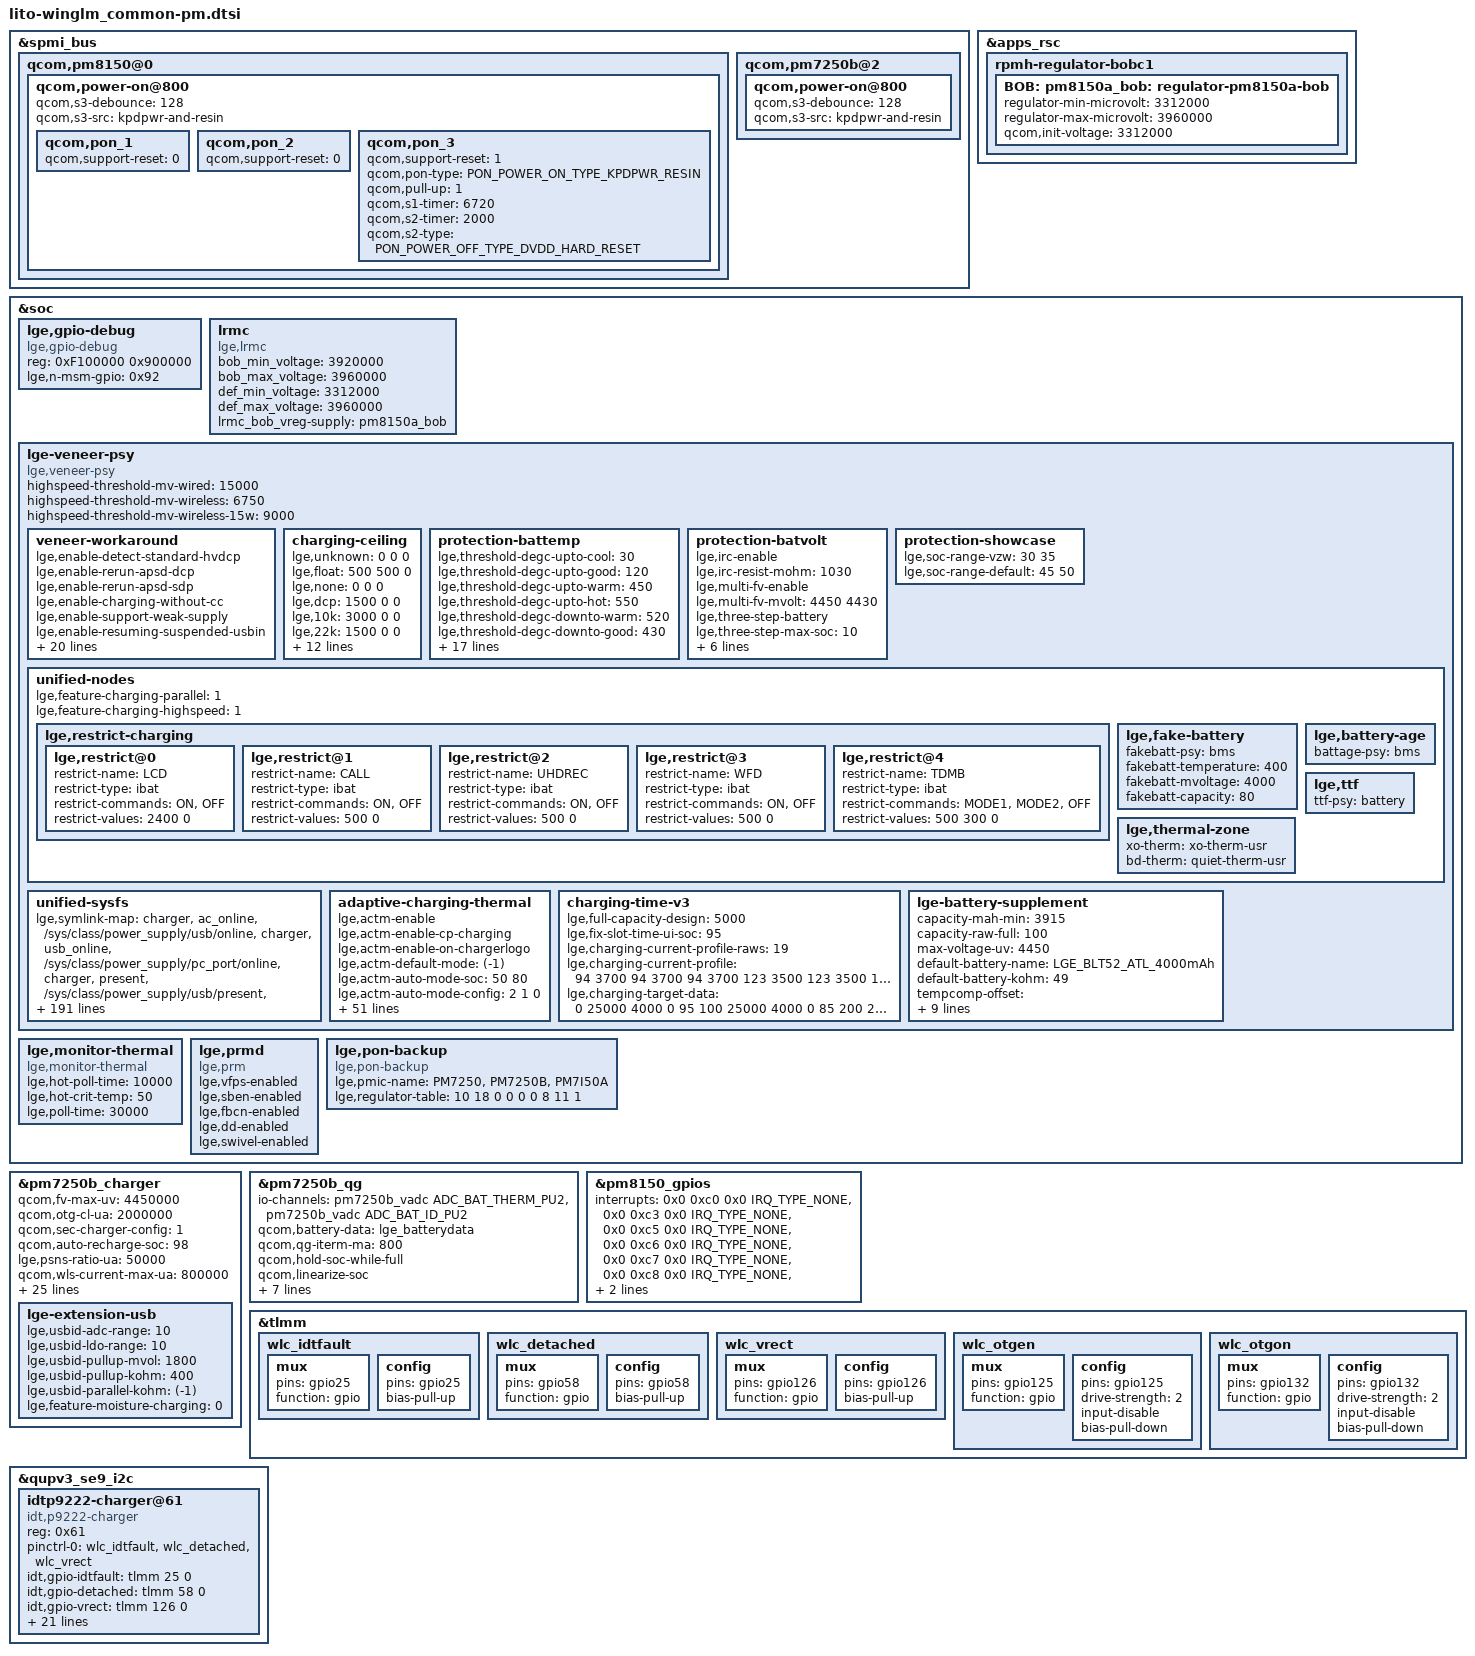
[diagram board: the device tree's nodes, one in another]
// SPDX-License-Identifier: GPL-2.0-only
/*
 * Copyright (c) 2018-2019, The Linux Foundation. All rights reserved.
 */

/* boot_images/QcomPkg/SocPkg/SaipanPkg/Settings/PMIC/pm_spmi_config.c */

&spmi_bus {
	qcom,pm8150@0 {
		qcom,power-on@800 {
			qcom,s3-debounce = <128>;
			qcom,s3-src = "kpdpwr-and-resin";

			qcom,pon_1 {
				/* KPD_PWR_N */
				status = "ok";
				qcom,support-reset = <0>;
			};

			qcom,pon_2 {
				/* RESIN_N */
				status = "ok";
				qcom,support-reset = <0>;
			};

			qcom,pon_3 {
				/* KPD_PWR_N AND RESIN_N */
				status = "ok";
				qcom,support-reset = <1>;
				qcom,pon-type = <PON_POWER_ON_TYPE_KPDPWR_RESIN>;
				qcom,pull-up = <1>;
				qcom,s1-timer = <6720>;
				qcom,s2-timer = <2000>;
				qcom,s2-type = <PON_POWER_OFF_TYPE_DVDD_HARD_RESET>;
			};
		};
	};

	qcom,pm7250b@2 {
		qcom,power-on@800 {
			qcom,s3-debounce = <128>;
			qcom,s3-src = "kpdpwr-and-resin";
		};
	};
};

&apps_rsc {
	rpmh-regulator-bobc1 {
		BOB: pm8150a_bob: regulator-pm8150a-bob {
			regulator-min-microvolt = <3312000>;
			regulator-max-microvolt = <3960000>;
			qcom,init-voltage = <3312000>;
		};
	};
};

&soc {
	lge,gpio-debug {
		compatible = "lge,gpio-debug";
		reg = <0xF100000 0x900000>;
		reg-names = "tlmm-base";
		lge,n-msm-gpio = <0x92>; /* SM7250 0 to 145 */
	};

	lrmc {
		compatible = "lge,lrmc";
		bob_min_voltage    = <3920000>;
		bob_max_voltage    = <3960000>;
		def_min_voltage    = <3312000>;
		def_max_voltage    = <3960000>;
		lrmc_bob_vreg-supply = <&pm8150a_bob>;
	};
	lge-veneer-psy {
		compatible = "lge,veneer-psy";
		status = "ok";
		highspeed-threshold-mv-wired = <15000>;
		highspeed-threshold-mv-wireless = <6750>;
		highspeed-threshold-mv-wireless-15w = <9000>;

		veneer-workaround {
			lge,enable-detect-standard-hvdcp;
			lge,enable-rerun-apsd-dcp;
			lge,enable-rerun-apsd-sdp;
			lge,enable-charging-without-cc;
			lge,enable-support-weak-supply;
			lge,enable-resuming-suspended-usbin;
			lge,enable-charging-with-rd;
			lge,enable-clear-power-role;
			//lge,enable-clear-dc-reverse-volt;
			lge,enable-clear-dc-reverse-volt-v2;
			lge,enable-avoid-fod-status;
			lge,enable-dcin-rerun-aicl;
			lge,enable-recovery-vashdn-wireless;
			lge,enable-retry-vconn-with-oc;
			lge,enable-retry-ok-to-pd;
			lge,enable-protect-overcharging;
			lge,enable-faked-usb-type;
			lge,enable-recover-cc;
			lge,enable-retry-apsd-with-factory;
			lge,enable-faster-try-apsd;
			lge,enable-faster-try;
			lge,enable-charging-for-mcdodo;
			lge,enable-disable-otg-hiccup;
			lge,enable-disable-cp-with-fake-mode;
			lge,enable-comp-cp-qc30;
			lge,enable-concurrency-otg-wlc;
			lge,enable-bad-operation-pps-ta;
		};

		charging-ceiling {
		/*	               iusb ibat  idc  : 0 means UNCEILING */
			lge,unknown = <   0    0    0>;
			lge,float   = < 500  500    0>;
			lge,none    = <   0    0    0>;

			lge,dcp     = <1500    0    0>;
			lge,10k     = <3000    0    0>;
			lge,22k     = <1500    0    0>;
			lge,qc2     = <1800    0    0>;
			lge,qc3     = <1800    0    0>;

			lge,usb2    = < 500    0    0>;
			lge,usb3    = < 900    0    0>;
			lge,cdp     = <1500 1500    0>;
			lge,pd      = <   0    0    0>;

			lge,56k     = <1500  500    0>;
			lge,130k    = <1500  500    0>;
			lge,910k    = <1500  500    0>;

			lge,w5w     = <   0    0  900>;
			lge,w9w     = <   0    0  900>;
			lge,w15w    = <   0    0 1200>;
		};

		protection-battemp {
			lge,threshold-degc-upto-cool = <30>;
			lge,threshold-degc-upto-good = <120>;
			lge,threshold-degc-upto-warm = <450>;
			lge,threshold-degc-upto-hot = <550>;
			lge,threshold-degc-downto-warm = <520>;
			lge,threshold-degc-downto-good = <430>;
			lge,threshold-degc-downto-cool = <100>;
			lge,threshold-degc-downto-cold = <0>;

			lge,period-ms-emergency	= <10000>;
			lge,period-ms-warning	= <30000>;
			lge,period-ms-normal	= <60000>;

		// parameters for warning status cool and warm
			lge,cool-mv-alert	= <4000>;
			lge,cool-ma-alert	= <500>;	// fixed 500 mA
			lge,cool-ma-pct		= <30>;		// means 0.3C rate

			lge,warm-mv-float	= <4000>;
			lge,warm-ma-pct		= <50>;		// means 0.5C rate

		// parameters for battery protection at chilly status
            lge,chilly-status-support;
            lge,chilly-degc-lowerbound = <0>;
            lge,chilly-degc-upperbound = <150>;
            lge,chilly-mv-alert    = <4000>;
            lge,chilly-mv-bound     = <200>;
            lge,chilly-ma-alert    = <630>;
            lge,chilly-ma-pct      = <50>;  // means 0.5C rate under batvol 4V
		};

		protection-batvolt {
			lge,irc-enable;
			lge,irc-resist-mohm = <1030>;
			lge,multi-fv-enable;
			lge,multi-fv-mvolt = <4450 4430>;  /* <CC_FV, CV_FV> */

			lge,three-step-battery;
			lge,three-step-max-soc = <10>;      // when soc exceed this value, disable maximum c-rate
			lge,threshold-vbat-limit = <4000 4200>;
			lge,threshold-vbat-clear = <3950 4150>;
			lge,threshold-ibat-pct = <100 60>;	// 1C = 3915mA, 0.6C = 2349mA
			// the below for two-step battery
			// lge,threshold-vbat-limit = <4250>;
			// lge,threshold-vbat-clear = <4200>;
			// lge,threshold-ibat-pct = <60>;	// means 0.6C rate

			lge,threshold-cv-ibat-pct = <34>;	// means 0.34C = 1331mA

			lge,step-ibat-ma = <100>;
			lge,step-poll-ms = <5000>;
		};

		protection-showcase {
			lge,soc-range-vzw     = <30 35>;
			lge,soc-range-default = <45 50>;
		};

		unified-nodes {
			lge,feature-charging-parallel = <1>;
			lge,feature-charging-highspeed = <1>;

			lge,restrict-charging {
				// restrict-values 0 means UNCEILING

				lge,restrict@0 {
					restrict-name = "LCD";
					restrict-type = "ibat";
					restrict-commands = "ON", "OFF";
					restrict-values = <2400      0>;
				};
				lge,restrict@1 {
					restrict-name = "CALL";
					restrict-type = "ibat";
					restrict-commands = "ON", "OFF";
					restrict-values = < 500      0>;
				};
				lge,restrict@2 {
					restrict-name = "UHDREC";
					restrict-type = "ibat";
					restrict-commands = "ON", "OFF";
					restrict-values = < 500      0>;
				};
				lge,restrict@3 {
					restrict-name = "WFD";
					restrict-type = "ibat";
					restrict-commands = "ON", "OFF";
					restrict-values = < 500      0>;
				};
				lge,restrict@4 {
					restrict-name = "TDMB";
					restrict-type = "ibat";
					restrict-commands = "MODE1", "MODE2", "OFF";
					restrict-values = <    500      300      0>;
				};
			};

			lge,fake-battery {
				fakebatt-psy = "bms";		// What 'psy' does implement(or support) the fake battery?
				fakebatt-temperature = <400>;
				fakebatt-mvoltage = <4000>;
				fakebatt-capacity = <80>;
			};

			lge,battery-age {
				battage-psy = "bms";		// What 'psy' does implement(or support) the battery age?
			};

			lge,thermal-zone {
				xo-therm = "xo-therm-usr";
				bd-therm = "quiet-therm-usr";
			};

			lge,ttf {
				ttf-psy = "battery";	// What 'psy' does implement(or support) the time to full now?
			};
		};

		unified-sysfs {
			lge,symlink-map =
			/* group , user_node, kernel node */
			/* Charger */
			"charger",                     "ac_online", "/sys/class/power_supply/usb/online",
			"charger",                    "usb_online", "/sys/class/power_supply/pc_port/online",
			"charger",                       "present", "/sys/class/power_supply/usb/present",
			"charger",                    "wlc_online", "/sys/class/power_supply/wireless/online",
			"charger",                          "type", "/sys/class/power_supply/usb/real_type",
			"charger",                   "usb_pd_type", "/sys/class/power_supply/usb/real_type",
			"charger",                      "time_out", "/sys/class/power_supply/battery/safety_timer_enabled",
			"charger",              "charging_enabled", "/sys/devices/platform/lge-unified-nodes/charging_enable",
			"charger",                  "ibat_current", "/sys/class/power_supply/battery/current_now",
			"charger",                  "ichg_current", "/sys/class/power_supply/usb/current_max",
			"charger",                  "iusb_control", "NULL",
			"charger",            "thermal_mitigation", "NULL",
			"charger",        "wlc_thermal_mitigation", "/sys/class/power_supply/wireless/current_max",
			"charger",       "usb_parallel_chg_status", "NULL",
			"charger", "usb_parallel_charging_enabled", "/sys/class/power_supply/charge_pump_master/charging_enabled",
			"charger", "factory_parallel_charger_test", "/sys/devices/platform/lge-unified-nodes/support_fastpl",
			"charger",            "moisture_detection", "/sys/class/power_supply/usb/moisture_detected",
			"charger",           "restricted_charging", "/sys/devices/platform/lge-unified-nodes/charging_restriction",
			"charger",              "ibat_max_current", "/sys/class/power_supply/battery/constant_charge_current_max",
			"charger",                       "chgstep", "/sys/devices/platform/lge-unified-nodes/charging_step",
			"charger",               "connection_type", "NULL",
			"charger",                       "fastchg", "/sys/devices/platform/lge-unified-nodes/charger_highspeed",
			"charger",         "input_current_settled", "/sys/class/power_supply/usb/input_current_settled",
			"charger",            "store_demo_enabled", "NULL",
			"charger",     "wireless_charging_enabled", "/sys/class/power_supply/wireless/charging_enabled",
			"charger",                 "input_suspend", "/sys/class/power_supply/battery/input_suspend",
			"charger",                  "incompatible", "/sys/devices/platform/lge-unified-nodes/charger_incompatible",
			"charger",                    "hvdcp_fake", "/sys/devices/platform/lge-unified-nodes/fake_hvdcp",
			"charger",               "usb_current_max", "/sys/devices/platform/lge-unified-nodes/fake_sdpmax",
			"charger",               "fastchg_support", "/sys/devices/platform/lge-unified-nodes/support_fastchg",
			"charger",                    "usbid_type", "/sys/class/power_supply/usb/resistance_id",
			"charger",          "typec_cc_orientation", "/sys/class/power_supply/usb/typec_cc_orientation",
			//"charger",                 "ccd_batchg_en", "/sys/devices/platform/lge-unified-nodes/ccd_batchg_en",
			//"charger",             "ccd_input_suspend", "/sys/devices/platform/lge-unified-nodes/ccd_input_suspend",
			//"charger",                       "ccd_icl", "/sys/devices/platform/lge-unified-nodes/ccd_icl",
			//"charger",                       "ccd_fcc", "/sys/devices/platform/lge-unified-nodes/ccd_fcc",
			//"charger",                    "ccd_vfloat", "/sys/devices/platform/lge-unified-nodes/ccd_vfloat",
			//"charger",                     "aicl_done", "/sys/devices/platform/lge-unified-nodes/aicl_done",
			/* ADC/MPP */
			"adc",              "thermal", "/sys/class/thermal/",
			"adc",             "xo_therm", "/sys/bus/iio/devices/iio:device0/in_temp_xo_therm_input",
			"adc",           "batt_therm", "/sys/class/power_supply/battery/temp",
			"adc",              "batt_id", "/sys/devices/platform/lge-unified-nodes/battery_valid",
			"adc",            "pa_therm1", "/sys/bus/iio/devices/iio:device0/in_temp_pa_therm1_input",
			"adc",            "pa_therm2", "/sys/bus/iio/devices/iio:device2/in_temp_pa_therm2_input",
			"adc",            "pa_therm3", "/sys/bus/iio/devices/iio:device1/in_temp_bmr_s_therm_input",
			"adc",           "quiet_therm","/sys/bus/iio/devices/iio:device1/in_temp_charger_skin_therm_input",
			"adc",               "usb_in", "/sys/class/power_supply/usb/voltage_now",
			"adc",                "vcoin", "/sys/bus/iio/devices/iio:device0/in_voltage_vcoin_input",
			"adc",              "vph_pwr", "/sys/bus/iio/devices/iio:device0/in_voltage_vph_pwr_input",
			"adc",               "usb_id", "/sys/devices/platform/lge-unified-nodes/charger_usbid",
			"adc",             "usb_edge", "NULL",
			"adc",                 "pmic", "/sys/class/thermal/thermal_zone53/temp",
			"adc",                  "vts", "/sys/bus/platform/drivers/monitor-thermal/soc:lge,monitor-thermal/vts_temp",
			/* Battery */
			"battery",         "capacity", "/sys/class/power_supply/battery/capacity",
			"battery",           "health", "/sys/class/power_supply/battery/health",
			"battery",          "present", "/sys/class/power_supply/battery/present",
			"battery",      "pseudo_batt", "/sys/devices/platform/lge-unified-nodes/fake_battery",
			"battery",           "status", "/sys/class/power_supply/battery/status",
			"battery",       "status_raw", "NULL",
			"battery",             "temp", "/sys/class/power_supply/battery/temp",
			"battery",    "valid_batt_id", "/sys/devices/platform/lge-unified-nodes/battery_valid",
			"battery",      "voltage_now", "/sys/class/power_supply/battery/voltage_now",
			"battery",          "vzw_chg", "/sys/devices/platform/lge-unified-nodes/charger_verbose",
			"battery",     "raw_capacity", "/sys/class/power_supply/bms/capacity_raw",
			"battery",        "condition", "/sys/devices/platform/lge-unified-nodes/battery_condition",
			"battery",      "battery_age", "/sys/devices/platform/lge-unified-nodes/battery_age",
			"battery","battery_age_level", "/sys/devices/platform/lge-unified-nodes/battery_age",
			"battery",            "cycle", "/sys/devices/platform/lge-unified-nodes/battery_cycle",
			"battery",     "battery_type", "/sys/class/power_supply/bms/battery_type",
			"battery",      "charge_full", "/sys/class/power_supply/bms/charge_full",
			"battery",   "charge_now_raw", "/sys/class/power_supply/bms/charge_now_raw",
			"battery", "time_to_full_now", "/sys/class/power_supply/battery/time_to_full_now",
			//"battery",     "ttf_capacity", "/sys/devices/platform/lge-unified-nodes/ttf_capacity",
			//"battery", "time_to_full_now", "/sys/devices/platform/lge-unified-nodes/time_to_full_now",
			//"battery",   "bsm_timetofull", "/sys/devices/platform/lge-unified-nodes/bsm_timetofull",
			/* LCD Backlight */
			"lcd",           "brightness", "/sys/class/backlight/panel0-backlight/brightness",
			"lcd",       "max_brightness", "/sys/class/backlight/panel0-backlight/max_brightness",
			"lcd_ex",        "brightness", "NULL",
			"lcd_ex",    "max_brightness", "NULL",
			/* KEY LED */
			"key_led",   "red_brightness", "/sys/class/leds/red/brightness",
			"key_led", "green_brightness", "/sys/class/leds/green/brightness",
			"key_led",  "blue_brightness", "/sys/class/leds/blue/brightness",
			/* CPU */
			"cpu",       "cpu_idle_modes", "NULL",
			/* GPU */
			"gpu",                 "busy", "/sys/class/kgsl/kgsl-3d0/gpubusy",
			"gpu",               "gpuclk", "/sys/class/kgsl/kgsl-3d0/gpuclk",
			/* PLATFORM */
			"platform",       "speed_bin", "NULL",
			"platform",         "pvs_bin", "NULL",
			"platform",   "poweron_alarm", "/sys/module/qpnp_rtc/parameters/poweron_alarm",
			"platform",         "pcb_rev", "/sys/bus/iio/devices/iio:device2/in_voltage_pmic_hardware_id_input",
			"platform",       "smpl_boot", "/sys/module/lge_smpl_count/parameters/smpl_boot",
			/* testmode */
			"testmode",            "temp", "/sys/class/power_supply/battery/temp",
			"testmode",     "voltage_now", "/sys/class/power_supply/battery/voltage_now",
			"testmode",          "usb_id", "/sys/devices/platform/lge-unified-nodes/charger_usbid",
			"testmode",         "batt_id", "/sys/devices/platform/lge-unified-nodes/battery_valid",
			"testmode",         "fuelval", "/sys/class/power_supply/battery/capacity",
			"testmode",        "xo_therm", "/sys/devices/platform/lge-unified-nodes/factory_xo_therm",
			"testmode",          "charge", "/sys/class/power_supply/battery/battery_charging_enabled",
			"testmode",          "chcomp", "/sys/devices/platform/lge-unified-nodes/charging_completed",
			"testmode",           "usbin", "/sys/class/power_supply/usb/voltage_now",
			"testmode",       "pa_therm1", "/sys/bus/iio/devices/iio:device0/in_temp_pa_therm1_input",
			"testmode",       "pa_therm2", "/sys/bus/iio/devices/iio:device2/in_temp_pa_therm2_input",
			"testmode",       "pa_therm3", "/sys/bus/iio/devices/iio:device1/in_temp_bmr_s_therm_input",
			"testmode",       "bd_therm2", "/sys/devices/platform/lge-unified-nodes/factory_bd_therm",
			"testmode",           "vcoin", "/sys/bus/iio/devices/iio:device0/in_voltage_vcoin_input",
			"testmode",         "vph_pwr", "/sys/bus/iio/devices/iio:device0/in_voltage_vph_pwr_input",
			"testmode",     "current_now", "/sys/class/power_supply/battery/current_now",
			"testmode",     "current_max", "/sys/class/power_supply/usb/current_max",
			"testmode",         "pcb_rev", "/sys/bus/iio/devices/iio:device2/in_voltage_pmic_hardware_id_input",
			"testmode",      "chgmodeoff", "/sys/class/power_supply/battery/input_suspend",
			"testmode",         "fuelrst", "/sys/class/power_supply/battery/present",
			"testmode",        "rtc_time", "/dev/rtc0",
			"testmode",           "pmrst", "NULL",
			"testmode",        "battexit", "/sys/class/power_supply/battery/present",
			"testmode",  "hardreset_mode", "NULL",
			/* ps feature*/
			"psfeature",     "vfps_ratio", "/sys/class/power/vfps/vfps_ratio",
			"psfeature",           "vfps", "/sys/class/power/vfps/vfps",
			"psfeature",      "vfps_fcnt", "/sys/class/power/vfps/vfps_fcnt",
			"psfeature",  "triton_policy", "/sys/class/power/triton/cur_policy",
			"psfeature",   "cancun_is_cm", "NULL",
			"regulator",       "vreg_bob", "/sys/devices/platform/soc/soc:lrmc/bob_mode";
		};

		adaptive-charging-thermal {
			lge,actm-enable;
			lge,actm-enable-cp-charging;                    // whether cp charging is supported.
			lge,actm-enable-on-chargerlogo;                 // the actm operates charging first mode in chargerlogo
			lge,actm-default-mode = <(-1)>;                 // 0-thermal first, 1-balanced, 2-charging first, 3-auto
			/*  actm auto mode description
			 *                     48%            77%
			 *    2-charging first  |  1-balacned  |  0-thermal first */
			lge,actm-auto-mode-soc = <50 80>;               // those values are raw soc.
			lge,actm-auto-mode-config = <2 1 0>;            // <2 1 0> means actm mode
			lge,actm-lcdon-temp-offset = <20>;              // unit: 0.1 degree

			lge,wired-therm-sensor-type = <21>;             // bit(0)-BATT, bit(1)-VTS, Two Digit -> <$(LCDON)$(LCDOFF)>
			lge,wired-wton-backward-margin = <10>;          // temp margin when it transit from WARM to NORM.
			lge,wired-temp-offset = <(-30) 0 0>;            // thermal first, balanced, charging first
			lge,wired-max-hold-criteria = <500 700 1000>;   // allow rising 1 degree per 20/14/10/min
			lge,wired-stage-size = <3>;
			lge,wired-target-temp = <300 340 380>;
			lge,wired-current-limit-ma = <3100 1500 500>;   // 0-normal, 1-warm, 2-hot
			lge,wired-curr-cp-limit-ma = <5100 3200>;       // extension of lge,wired-current-limit-ma
			                                                // 0-normal & pps, 1-normal & qc3.0
			lge,wired-max-fcc-ma = <5100 3200 3100>;        // 0-pps ta, 1- qc3.0 ta, 2-qc2.0 ta
			lge,wired-current-step-size = <3>;
			lge,wired-current-step-temp = <5 15 30>;
			lge,wired-current-step-ma = <100 200 400>;
			lge,wired-timer-ms = <60000>;

			/* wired sidecar */
			lge,wired-sidecar-enable = <0 0 1>;             // <Thermal first, balanced, charging first>
			lge,wired-sidecar-therm-enter-temp = <380 400>;     // <LCD_OFF, LCD_ON>
			lge,wired-sidecar-therm-exit-temp = <370 390>;      // <LCD_OFF, LCD_ON>
			lge,wired-sidecar-therm-min-current = <1000 500>;   // <LCD_OFF, LCD_ON>
			lge,wired-sidecar-bal-enter-temp = <380 400>;       // <LCD_OFF, LCD_ON>
			lge,wired-sidecar-bal-exit-temp = <370 390>;        // <LCD_OFF, LCD_ON>
			lge,wired-sidecar-bal-min-current = <1000 500>;     // <LCD_OFF, LCD_ON>
			lge,wired-sidecar-chg-enter-temp = <380 400>;       // <LCD_OFF, LCD_ON>
			lge,wired-sidecar-chg-exit-temp = <370 390>;        // <LCD_OFF, LCD_ON>
			lge,wired-sidecar-chg-min-current = <1000 500>;     // <LCD_OFF, LCD_ON>

			lge,wireless-therm-sensor-type = <33>;          // bit(0)-BATT, bit(1)-VTS, Two Digit -> <$(LCDON)$(LCDOFF)>
			lge,wireless-wton-backward-margin = <0>;        // temp margin when it transit from WARM to NORM.
			lge,wireless-temp-offset = <(-30) 0 0>;         // thermal first, balanced, charging first
			lge,wireless-max-hold-criteria = <250 333 500>; // allow rising 1 degree per 40/30/20min
			lge,wireless-stage-size = <3>;
			lge,wireless-target-temp = <320 380 420>;
			lge,wireless-epp-power-limit-mw = <6300 4050 3000>;
			lge,wireless-bpp-power-limit-mw = <4200 3900 3000>;
			lge,wireless-15w-max-power-mw = <0 0 7200>; // <Thermal first, balanced, charging first>
			lge,wireless-power-step-size = <3>;
			lge,wireless-power-step-temp = <5 15 30>;
			lge,wireless-epp-power-step-mw = <450 900 1350>;
			lge,wireless-bpp-power-step-mw = <300 600 900>;
			lge,wireless-timer-ms = <60000>;

			/* wireless sidecar */
			lge,wireless-sidecar-enable = <0 0 1>;          // <Thermal first, balanced, charging first>
			lge,wireless-sidecar-therm-enter-temp = <420 420>;  // <LCD_OFF, LCD_ON>
			lge,wireless-sidecar-therm-exit-temp = <400 400>;   // <LCD_OFF, LCD_ON>
			lge,wireless-sidecar-therm-min-power = <3000 3000>; // <LCD_OFF, LCD_ON>
			lge,wireless-sidecar-bal-enter-temp = <420 420>;    // <LCD_OFF, LCD_ON>
			lge,wireless-sidecar-bal-exit-temp = <400 400>;     // <LCD_OFF, LCD_ON>
			lge,wireless-sidecar-bal-min-power = <3000 3000>;   // <LCD_OFF, LCD_ON>
			lge,wireless-sidecar-chg-enter-temp = <420 420>;    // <LCD_OFF, LCD_ON>
			lge,wireless-sidecar-chg-exit-temp = <400 400>;     // <LCD_OFF, LCD_ON>
			lge,wireless-sidecar-chg-min-power = <3000 3000>;   // <LCD_OFF, LCD_ON>
		};

		charging-time-v3 {
			lge,full-capacity-design = <5000>;
			lge,fix-slot-time-ui-soc = <95>;

			lge,charging-current-profile-raws = <19>;  /* max: 20 */
			lge,charging-current-profile = <
			/* format: raw_soc, raw_current(mA) */
			/* | Thermal |  | Balanced | | Charging | */
				 94  3700     94  3700     94  3700
				123  3500    123  3500    123  3500
				139  3400    139  3400    139  3400
				153  3300    153  3300    153  3300
				164  3000    164  3000    164  3000
				178  2600    178  2600    178  2600
				181  2300    181  2300    181  2300
				221  2200    221  2200    221  2200
				233  1800    233  1800    233  1800
				239  1500    239  1500    239  1500
				245  1300    245  1300    245  1300
				247  1220    247  1220    247  1220
				248  1170    248  1170    248  1170
				249  1100    249  1100    249  1100
				250  1040    250  1040    250  1040
				251   960    251   960    251   960
				252   900    252   900    252   900
				253   850    253   850    253   850
				254   800    254   800    254   800   /* <- END -> */
			>;

			lge,charging-target-data = <
	/* format : type, power(mW), current(mA), down(uA), target(min) */
	/* cp pps  thermal  */    0    25000    4000       0     95
	/*         balanced */  100    25000    4000       0     85
	/*         charging */  200    25000    4850       0     80
	/* CP QC3  thermal  */    1    16200    3000       0    105
	/*         balanced */  101    16200    3000       0     95
	/*         charging */  201    16200    3200       0     90
	/* QC2     thermal  */    2    15000    2600       0    105
	/*         balanced */  102    15000    2600       0     95
	/*         charging */  202    15000    3100       0     90
	/* DCP     thermal  */    2     7500    1650     881    150
	/*         balanced */  102     7500    1650     881    150
	/*         charging */  202     7500    1650     881    150
	/* SDP     thermal  */    2     2500     500       0    485
	/*         balanced */  102     2500     500       0    485
	/*         charging */  202     2500     500       0    485
	/* WLC EPP thermal  */    3     7200    1750    2224    190
	/*         balanced */  103     7200    1750    2224    190
	/*         charging */  203     7200    1750    1032    175
	/* WLC BPP thermal  */    3     4500    1100     920    225
	/*         balanced */  103     4500    1100     920    225
	/*         charging */  203     4500    1100     640    205
	/* BCC     thermal  */    4    12500    2000       0    125
	/*         balanced */  104    12500    2000       0    125
	/*         charging */  204    12500    2000       0    125
			>;
		};

		lge-battery-supplement {
			capacity-mah-min = <3915>;
			capacity-raw-full = <100>;
			max-voltage-uv = <4450>;

			default-battery-name = "LGE_BLT52_ATL_4000mAh";
			default-battery-kohm = <49>;

			/* format : (temp index) (temp delta) */
			tempcomp-offset = <
				(-300) (-45)
				(-222) (-28)
				(-178) (-22)
				(-130) (-20)
				( -79) (-21)
				( -31) (-19)
				( -10) (-17)
				   15  (-15)
				   63  (-13)
				  110  (-10)
				  159  ( -9)
				  208  ( -9)
				  257  ( -7)
				  306  ( -7)
				  356  ( -6)
				  405  ( -5)
				  456  ( -6)
				  507  ( -7)
				  557  ( -8)
				  609  (-10)
				  662  (-13)
				  700  (-13)
				  730  (-13)
				  750  (-13)
				  800  (-13)
			>;

			tempcomp-offset-wlc-enable;
			tempcomp-offset-wlc-rise-filter-trigger = <430>;
			tempcomp-offset-wlc-lcdoff = <
				(-300) (-45)
				(-222) (-28)
				(-178) (-22)
				(-130) (-20)
				( -79) (-21)
				( -31) (-19)
				( -10) (-17)
				   15  (-15)
				   63  (-13)
				  110  (-10)
				  159  ( -9)
				  208  ( -9)
				  257    12
				  306    12
				  356    15
				  405    15
				  456    15
				  507    15
				  557  ( -8)
				  609  (-10)
				  662  (-13)
				  700  (-13)
				  730  (-13)
				  750  (-13)
				  800  (-13)
			>;

			tempcomp-offset-wlc-lcdon = <
				(-300) (-45)
				(-222) (-28)
				(-178) (-22)
				(-130) (-20)
				( -79) (-21)
				( -31) (-19)
				( -10) (-17)
				   15  (-15)
				   63  (-13)
				  110  (-10)
				  159  ( -9)
				  208  ( -9)
				  257    12
				  306    12
				  356    15
				  405    15
				  456    15
				  507    15
				  557  ( -8)
				  609  (-10)
				  662  (-13)
				  700  (-13)
				  730  (-13)
				  750  (-13)
				  800  (-13)
			>;

			tempcomp-smooth-filter-enable;
			tempcomp-icoeff = <20>;
		};
	};

	lge,monitor-thermal {
		compatible = "lge,monitor-thermal";
		lge,hot-poll-time = <10000>;
		lge,hot-crit-temp = <50>;
		lge,poll-time = <30000>;
	};

	lge,prmd {
		compatible = "lge,prm";
		lge,vfps-enabled;
		lge,sben-enabled;
		lge,fbcn-enabled;
		lge,dd-enabled;
		lge,swivel-enabled;
	};

	lge,pon-backup {
		compatible = "lge,pon-backup";
		lge,pmic-name =
			"PM7250",
			"PM7250B",
			"PM7I50A";
		lge,regulator-table = <
		/*                 SPMS LDO BOB */
		/* 0 - PM7250   */   10  18   0
		/* 1 - PM7250B */    0   0   0
		/* 2 - PM7I50A */    8  11   1
		>;
	};
};

&pm7250b_charger {
    status = "ok";
	qcom,fv-max-uv=<4450000>;
    qcom,otg-cl-ua=<2000000>;
    qcom,sec-charger-config = <1>;
    qcom,auto-recharge-soc = <98>;
    lge,psns-ratio-ua = <50000>;
    qcom,wls-current-max-ua = <800000>;
    io-channels = <&pm7250b_vadc ADC_MID_CHG_DIV6>,
              <&pm7250b_vadc ADC_USB_IN_V_16>,
              <&pm7250b_vadc ADC_USB_IN_I>,
              <&pm7250b_vadc ADC_CHG_TEMP>,
              <&pm7250b_vadc ADC_DIE_TEMP>,
              <&pm7250b_vadc ADC_AMUX_THM3_PU2>,
              <&pm7250b_vadc ADC_SBUx>,
              <&pm7250b_vadc ADC_VPH_PWR>,
              <&pm8150l_vadc ADC_AMUX_THM2_PU3>;
    io-channel-names = "mid_voltage",
               "usb_in_voltage",
               "usb_in_current",
               "chg_temp",
               "die_temp",
               "conn_temp",
               "sbux_res",
               "vph_voltage",
               "usb_id";
    qcom,battery-data = <&lge_batterydata>;
    qcom,step-charging-enable;
    /delete-property/ qcom,sw-jeita-enable;
    qcom,charger-temp-max = <800>;
    qcom,smb-temp-max = <800>;
    qcom,suspend-input-on-debug-batt;
    qcom,fcc-stepping-enable;
    qcom,chg-term-src = <1>;
    qcom,chg-term-current-ma = <(-190)>;
    lge,vconn-boost-en = <&pm8150l_gpios 1 GPIO_ACTIVE_HIGH>;
    lge,prot-overchg-ent-dischg-off-uv = <10000>;
    lge,prot-overchg-ent-chg-off-uv = <20000>;
    lge,prot-overchg-rel-off-uv = <50000>;

    lge-extension-usb {
        lge,usbid-adc-range = <10>;		// ADC margin (pct unit)
        lge,usbid-ldo-range = <10>;		// LDO margin (pct unit)
        lge,usbid-pullup-mvol = <1800>;		// Pull-up voltage
        lge,usbid-pullup-kohm = <400>;		// Pull-up resistance
        lge,usbid-parallel-kohm = <(-1)>;	// Pull-up resistance

        lge,feature-moisture-charging = <0>;
    };
};

&pm7250b_qg {
    status = "ok";
    io-channels = <&pm7250b_vadc ADC_BAT_THERM_PU2>,
              <&pm7250b_vadc ADC_BAT_ID_PU2>;
    io-channel-names = "batt-therm",
               "batt-id";
    qcom,battery-data = <&lge_batterydata>;
    qcom,qg-iterm-ma = <800>;
    qcom,hold-soc-while-full;
    qcom,linearize-soc;
    qcom,cl-feedback-on;
    qcom,cl-min-start-soc = <0>;
    qcom,s3-entry-ibat-ua = <50000>;
    qcom,s3-exit-ibat-ua = <55000>;
    qcom,qg-fast-chg-config;
    qcom,fast-chg-s2-fifo-length = <2>;
    qcom,s2-fifo-length = <4>;
};

&pm8150_gpios {
	interrupts = <0x0 0xc0 0x0 IRQ_TYPE_NONE>,
			<0x0 0xc3 0x0 IRQ_TYPE_NONE>,
			<0x0 0xc5 0x0 IRQ_TYPE_NONE>,
			<0x0 0xc6 0x0 IRQ_TYPE_NONE>,
			<0x0 0xc7 0x0 IRQ_TYPE_NONE>,
			<0x0 0xc8 0x0 IRQ_TYPE_NONE>,
			<0x0 0xc9 0x0 IRQ_TYPE_NONE>;
	interrupt-names = "pm8150_gpio1", "pm8150_gpio4", "pm8150_gpio6",
			"pm8150_gpio7", "pm8150_gpio8",
			"pm8150_gpio9", "pm8150_gpio10";
	qcom,gpios-disallowed = <2 3 5>;
};

&tlmm {
	wlc_idtfault: wlc_idtfault {
		mux {
			pins = "gpio25";
			function = "gpio";
		};

		config {
			pins = "gpio25";
			bias-pull-up;
		};
	};

	wlc_detached: wlc_detached {
		mux {
			pins = "gpio58";
			function = "gpio";
		};

		config {
			pins = "gpio58";
			bias-pull-up;
		};
	};

	wlc_vrect: wlc_vrect {
		mux {
			pins = "gpio126";
			function = "gpio";
		};

		config {
			pins = "gpio126";
			bias-pull-up;
		};
	};

	wlc_otgen: wlc_otgen {
		mux {
			pins = "gpio125";
			function = "gpio";
		};
		config {
			pins = "gpio125";
			drive-strength = <2>;
			input-disable;
			bias-pull-down;
		};
	};

	wlc_otgon: wlc_otgon {
		mux {
			pins = "gpio132";
			function = "gpio";
		};
		config {
			pins = "gpio132";
			drive-strength = <2>;
			input-disable;
			bias-pull-down;
		};
	};
};

&qupv3_se9_i2c {
	idtp9222-charger@61 {					// Slave driver and slave Address
		compatible ="idt,p9222-charger";	// Manufacture, model
		reg = <0x61>;						// Slave Address
		status = "ok";

		// one time calling of pinctrl.
		// pinctrl-0 is the permanent configuraion of MSM GPIOs
		pinctrl-names = "wlc_pinctrl";
		pinctrl-0 = <&wlc_idtfault &wlc_detached &wlc_vrect>;

		idt,gpio-idtfault = <&tlmm 25 0>;
		idt,gpio-detached = <&tlmm 58 0>;
		idt,gpio-vrect = <&tlmm 126 0>;
		idt,gpio-disabled = <&pm7250b_gpios 3 0>;

		idt,fod-legacy = [ FF 7F FF 7F
				FF 7F FF 7F
				FF 7F FF 7F ];

		idt,fod-epp = [ A5 3B 88 44
				86 46 96 19
				94 10 94 10
				14 00 A0 50 ];

		idt,fod-bpp = [ A5 28 88 2E
				98 19 A0 02
				9F 00 A8 E8
				14 00 00 00 ];

		idt,configure-bppcurr = <750000>;
		idt,configure-eppcurr = <800000>;
		idt,configure-maxcurr = <950000>;
		idt,configure-fullcurr = <500000>;
		idt,configure-bppvolt = <6000000>;
		idt,configure-eppvolt = <9000000>;
		idt,configure-maxvolt = <12000000>;
		idt,configure-overheat = <450>;		// Temperature threshold to send EPT_BY_OVERTEMP
		idt,configure-sysfs;				// For debug sysfs
		idt,configure-charge-done;
		idt,probation-enable;
		idt,probation-delay = <120000>;     /* 2min  */
		idt,probation-bppcurr = <400000>;   /* 400mA */
		idt,probation-eppcurr = <600000>;   /* 600mA */
	};
};

&pm7250b_charger {
	pinctrl-names = "wlc_otg_pinctrl";
	pinctrl-0 = <&wlc_otgen &wlc_otgon>;

	lge,wireless-otg-en = <&tlmm 125 0>;
	lge,wireless-otg-on = <&tlmm 132 0>;
};

